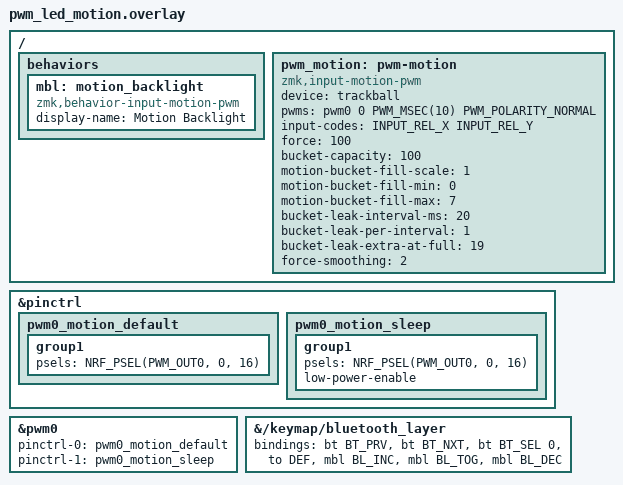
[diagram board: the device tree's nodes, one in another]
#include <dt-bindings/zmk/backlight.h>
#include <zephyr/dt-bindings/input/input-event-codes.h>
#include <zephyr/dt-bindings/pwm/pwm.h>

/ {
    behaviors {
        mbl: motion_backlight {
            compatible = "zmk,behavior-input-motion-pwm";
            #binding-cells = <2>;
            display-name = "Motion Backlight";
        };
    };

    pwm_motion: pwm-motion {
        compatible = "zmk,input-motion-pwm";
        device = <&trackball>;
        pwms = <&pwm0 0 PWM_MSEC(10) PWM_POLARITY_NORMAL>;
        input-codes = <INPUT_REL_X INPUT_REL_Y>;

        force = <100>;
        bucket-capacity = <100>;
        motion-bucket-fill-scale = <1>;
        motion-bucket-fill-min = <0>;
        motion-bucket-fill-max = <7>;
        bucket-leak-interval-ms = <20>;
        bucket-leak-per-interval = <1>;
        bucket-leak-extra-at-full = <19>;
        force-smoothing = <2>;
    };
};

&pinctrl {
    pwm0_motion_default: pwm0_motion_default {
        group1 {
            psels = <NRF_PSEL(PWM_OUT0, 0, 16)>;
        };
    };

    pwm0_motion_sleep: pwm0_motion_sleep {
        group1 {
            psels = <NRF_PSEL(PWM_OUT0, 0, 16)>;
            low-power-enable;
        };
    };
};

&pwm0 {
    status = "okay";
    pinctrl-0 = <&pwm0_motion_default>;
    pinctrl-1 = <&pwm0_motion_sleep>;
    pinctrl-names = "default", "sleep";
};

&{/keymap/bluetooth_layer} {
    bindings = <
        &bt BT_PRV &bt BT_NXT
        &bt BT_SEL 0 &to DEF
        &mbl BL_INC &mbl BL_TOG &mbl BL_DEC
    >;
};
